VERSION "Mon"

NS_ :

BS_:

BU_: Mon ADAS Camera Gateway EPS APA Radar ESC radar
VAL_TABLE_ VitSig_LKA_main_switch 1 "LKA ON" 0 "LKA OFF" ;
VAL_TABLE_ VitSig_LC_Mode 3 "车道居中控制" 2 "车道保持辅助" 1 "车道偏离预警" 0 "预留" ;
VAL_TABLE_ VitSig_State_of_EPS_for_LKA 7 "Reserved" 6 "Reserved" 5 "Reserved" 4 "defect" 3 "active" 2 "available" 1 "authorized" 0 "unauthorized" ;
VAL_TABLE_ VitSig_Steering_wheel_sensor_dir 1 "Negative angles, decrease" 0 "Positive angles, increase" ;
VAL_TABLE_ VitSig_BCM_Status_Indicator 3 "Left and right indicator active" 2 "Left Indicator active" 1 "Right Indicator active" 0 "Indicator inactive" ;
VAL_TABLE_ VitSig_TCU_Gear_lever_position 15 "CMF disabled or unavailable" 14 "Reserved" 13 "Reserved" 12 "Reserved" 11 "Manual mode / Reserved1100" 10 "Reserved" 9 "Reserved" 8 "Reserved" 7 "Reserved" 6 "Reserved" 5 "Reserved" 4 "Reserved" 3 "D" 2 "N" 1 "R" 0 "P" ;
VAL_TABLE_ VLlaneType_valueTable 6 "road edge" 5 "bott's dotts" 4 "double lane mark" 3 "solid" 2 "dashed" 1 "undecided" 0 "invalid" ;
VAL_TABLE_ VLquality_valueTable 1 "high" 0 "low" ;

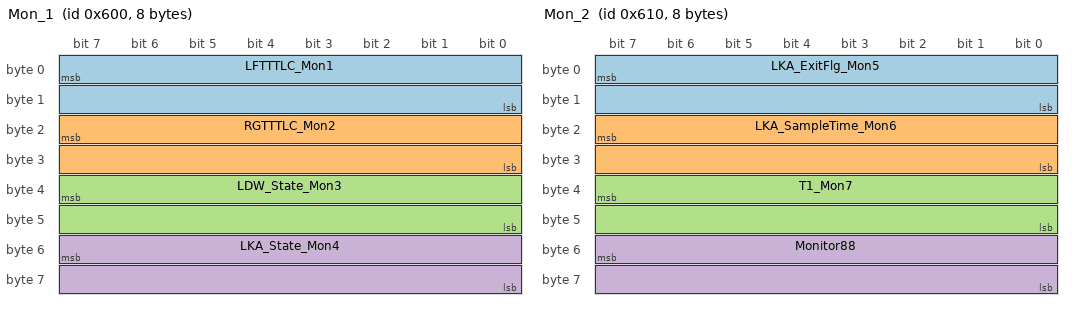
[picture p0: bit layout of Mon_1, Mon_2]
BO_ 1536 Mon_1: 8 Mon
 SG_ LFTTTLC_Mon1 : 7|16@0- (0.01,0) [-327.68|327.67] "Mon" Vector__XXX
 SG_ RGTTTLC_Mon2 : 23|16@0- (0.01,0) [-327.68|327.67] "Mon" Vector__XXX
 SG_ LDW_State_Mon3 : 39|16@0- (0.01,0) [-327.68|327.67] "Mon" Vector__XXX
 SG_ LKA_State_Mon4 : 55|16@0- (0.01,0) [-327.68|327.67] "Mon" Vector__XXX

BO_ 1552 Mon_2: 8 Mon
 SG_ LKA_ExitFlg_Mon5 : 7|16@0- (0.01,0) [-327.68|327.67] "Mon" Vector__XXX
 SG_ LKA_SampleTime_Mon6 : 23|16@0- (0.01,0) [-327.68|327.67] "Mon" Vector__XXX
 SG_ T1_Mon7 : 39|16@0- (0.01,0) [-327.68|327.67] "Mon" Vector__XXX
 SG_ Monitor88 : 55|16@0- (0.01,0) [-327.68|327.67] "Mon" Vector__XXX

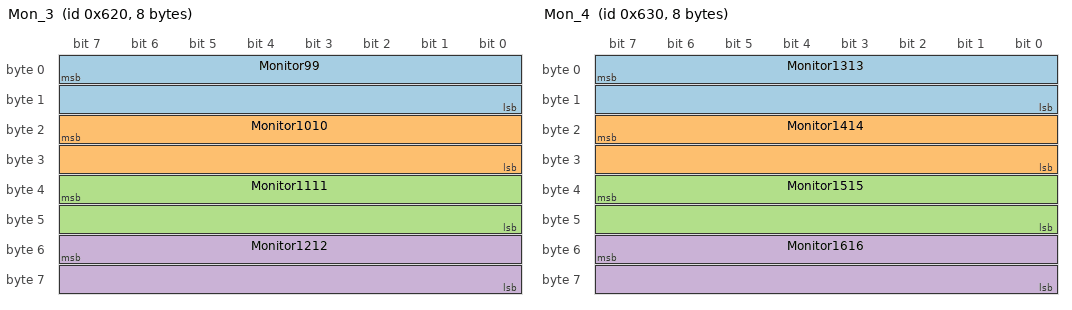
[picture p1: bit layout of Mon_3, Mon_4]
BO_ 1568 Mon_3: 8 Mon
 SG_ Monitor99 : 7|16@0- (0.01,0) [-327.68|327.67] "Mon" Vector__XXX
 SG_ Monitor1010 : 23|16@0- (0.01,0) [-327.68|327.67] "Mon" Vector__XXX
 SG_ Monitor1111 : 39|16@0- (0.01,0) [-327.68|327.67] "Mon" Vector__XXX
 SG_ Monitor1212 : 55|16@0- (0.01,0) [-327.68|327.67] "Mon" Vector__XXX

BO_ 1584 Mon_4: 8 Mon
 SG_ Monitor1313 : 7|16@0- (0.01,0) [-327.68|327.67] "Mon" Vector__XXX
 SG_ Monitor1414 : 23|16@0- (0.01,0) [-327.68|327.67] "Mon" Vector__XXX
 SG_ Monitor1515 : 39|16@0- (0.01,0) [-327.68|327.67] "Mon" Vector__XXX
 SG_ Monitor1616 : 55|16@0- (0.01,0) [-327.68|327.67] "Mon" Vector__XXX

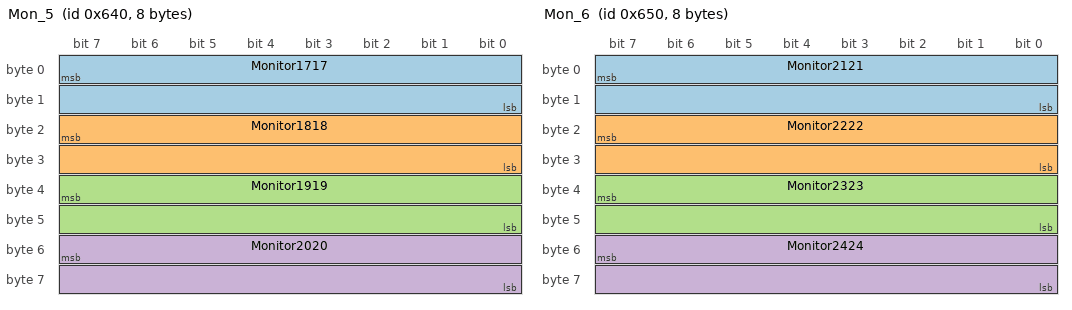
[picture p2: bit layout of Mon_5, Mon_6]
BO_ 1600 Mon_5: 8 Mon
 SG_ Monitor1717 : 7|16@0- (0.01,0) [-327.68|327.67] "Mon" Vector__XXX
 SG_ Monitor1818 : 23|16@0- (0.01,0) [-327.68|327.67] "Mon" Vector__XXX
 SG_ Monitor1919 : 39|16@0- (0.01,0) [-327.68|327.67] "Mon" Vector__XXX
 SG_ Monitor2020 : 55|16@0- (0.01,0) [-327.68|327.67] "Mon" Vector__XXX

BO_ 1616 Mon_6: 8 Mon
 SG_ Monitor2121 : 7|16@0- (0.01,0) [-327.68|327.67] "Mon" Vector__XXX
 SG_ Monitor2222 : 23|16@0- (0.01,0) [-327.68|327.67] "Mon" Vector__XXX
 SG_ Monitor2323 : 39|16@0- (0.01,0) [-327.68|327.67] "Mon" Vector__XXX
 SG_ Monitor2424 : 55|16@0- (0.01,0) [-327.68|327.67] "Mon" Vector__XXX

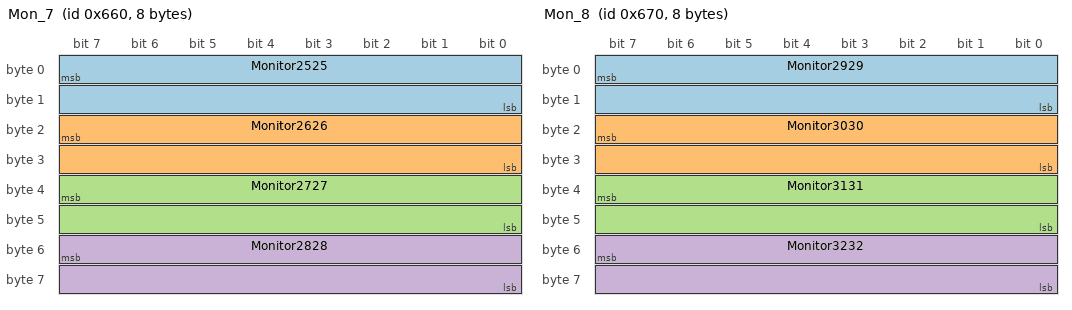
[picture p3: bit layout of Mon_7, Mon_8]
BO_ 1632 Mon_7: 8 Mon
 SG_ Monitor2525 : 7|16@0- (0.01,0) [-327.68|327.67] "Mon" Vector__XXX
 SG_ Monitor2626 : 23|16@0- (0.01,0) [-327.68|327.67] "Mon" Vector__XXX
 SG_ Monitor2727 : 39|16@0- (0.01,0) [-327.68|327.67] "Mon" Vector__XXX
 SG_ Monitor2828 : 55|16@0- (0.01,0) [-327.68|327.67] "Mon" Vector__XXX

BO_ 1648 Mon_8: 8 Mon
 SG_ Monitor2929 : 7|16@0- (0.01,0) [-327.68|327.67] "Mon" Vector__XXX
 SG_ Monitor3030 : 23|16@0- (0.01,0) [-327.68|327.67] "Mon" Vector__XXX
 SG_ Monitor3131 : 39|16@0- (0.01,0) [-327.68|327.67] "Mon" Vector__XXX
 SG_ Monitor3232 : 55|16@0- (0.01,0) [-327.68|327.67] "Mon" Vector__XXX

BO_ 1359 GW_550_PSA1: 8 Gateway
 SG_ LKA_main_switch : 5|1@0+ (1,0) [0|1] ""  ADAS,Camera
 SG_ LC_Mode : 7|2@0+ (1,0) [0|3] ""  ADAS,Camera

BO_ 1172 EPS_495_PSA1: 4 EPS
 SG_ State_of_EPS_for_LKA_function : 20|3@0+ (1,0) [0|7] ""  ADAS,Camera
 SG_ Steering_wheel_torque : 7|8@0- (0.25,0) [-32|31.5] "N.m"  ADAS,Camera

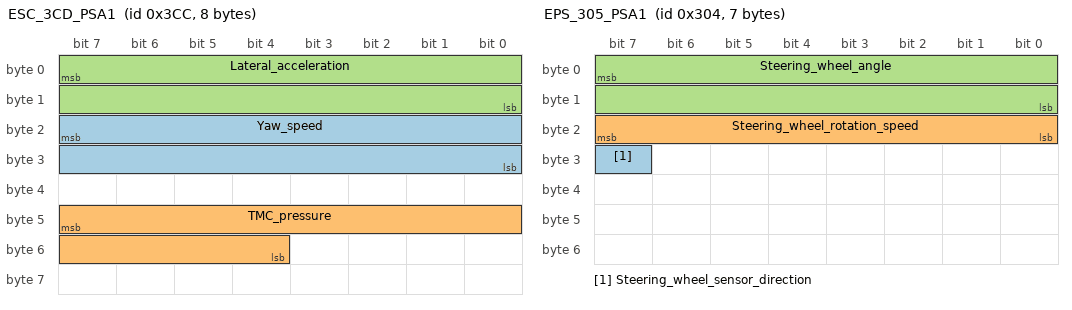
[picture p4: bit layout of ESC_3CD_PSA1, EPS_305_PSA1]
BO_ 972 ESC_3CD_PSA1: 8 ESC
 SG_ Yaw_speed : 23|16@0- (0.1,0) [-100|100] "Degree/s"  EPS,Gateway,APA,Camera,ADAS
 SG_ TMC_pressure : 47|12@0+ (0.1,-55) [-55|354.4] "Bar"  Gateway,APA,Radar,Camera,ADAS
 SG_ Lateral_acceleration : 7|16@0- (0.05,0) [-15|15] "m/s2"  EPS,Gateway,APA,Radar,Camera,ADAS

BO_ 908 ESC_38D_PSA1: 8 ESC
 SG_ Vehicle_speed_of_wheelsensor : 7|16@0+ (0.01,0) [0|655.34] "km/h"  EPS,Gateway,APA,Radar,Camera,ADAS

BO_ 812 GW_32D_PSA1: 8 Gateway
 SG_ ACCEL_LONGI_CALIB : 7|12@0+ (0.02,-40.96) [-40.96|40.92] "m/s2"  Radar,Camera,ADAS

BO_ 772 EPS_305_PSA1: 7 EPS
 SG_ Steering_wheel_sensor_direction : 31|1@0+ (1,0) [0|0] ""  ADAS,Camera,ESC,Gateway,Radar
 SG_ Steering_wheel_rotation_speed : 23|8@0+ (4,0) [0|1016] "Degree/s"  ADAS,APA,Camera,ESC,Gateway,Radar
 SG_ Steering_wheel_angle : 7|16@0- (0.1,0) [-780|780] "Degree"  ADAS,APA,Camera,ESC,Gateway,Radar

BO_ 1105 GW_452_PSA1: 6 Gateway
 SG_ BCM_Status_Indicator : 5|2@0+ (1,0) [0|0] ""  APA,Radar,Camera,ADAS

BO_ 840 GW_349_PSA1: 8 Gateway
 SG_ TCU_Gear_lever_position : 27|4@0+ (1,0) [0|0] ""  ESC,APA,Radar,Camera,ADAS

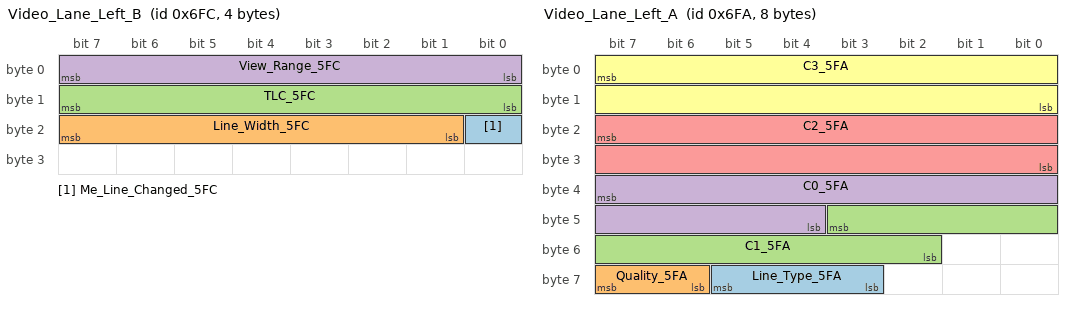
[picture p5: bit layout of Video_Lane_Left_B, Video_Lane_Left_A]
BO_ 1788 Video_Lane_Left_B: 4 Camera
 SG_ Me_Line_Changed_5FC : 16|1@0+ (1,0) [0|1] ""  radar,ADAS
 SG_ Line_Width_5FC : 23|7@0+ (0.01,0) [0|1.27] "m"  radar,ADAS
 SG_ TLC_5FC : 15|8@0+ (0.01,0) [0|2.55] "s"  radar,ADAS
 SG_ View_Range_5FC : 7|8@0+ (0.5,0) [0|127.5] "m"  radar,ADAS

BO_ 1786 Video_Lane_Left_A: 8 Camera
 SG_ Line_Type_5FA : 61|3@0+ (1,0) [0|7] ""  radar,ADAS
 SG_ Quality_5FA : 63|2@0+ (1,0) [0|3] ""  radar,ADAS
 SG_ C1_5FA : 43|10@0- (0.0009765625,0) [-0.357|0.357] ""  radar,ADAS
 SG_ C0_5FA : 39|12@0- (0.01,0) [-20.48|20.47] "m"  radar,ADAS
 SG_ C2_5FA : 23|16@0- (1E-006,0) [-0.032768|0.032766] "m-1"  radar,ADAS
 SG_ C3_5FA : 7|16@0- (4E-009,0) [-0.000131072|0.000131068] "m-2"  radar,ADAS

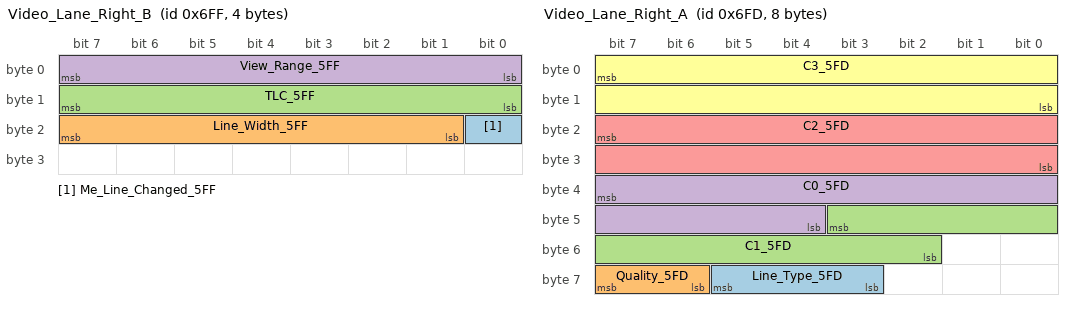
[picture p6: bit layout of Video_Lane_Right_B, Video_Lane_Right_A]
BO_ 1791 Video_Lane_Right_B: 4 Camera
 SG_ Me_Line_Changed_5FF : 16|1@0+ (1,0) [0|1] ""  radar,ADAS
 SG_ Line_Width_5FF : 23|7@0+ (0.01,0) [0|1.27] "m"  radar,ADAS
 SG_ TLC_5FF : 15|8@0+ (0.01,0) [0|2.55] "s"  radar,ADAS
 SG_ View_Range_5FF : 7|8@0+ (0.5,0) [0|127.5] "m"  radar,ADAS

BO_ 1789 Video_Lane_Right_A: 8 Camera
 SG_ Line_Type_5FD : 61|3@0+ (1,0) [0|7] ""  radar,ADAS
 SG_ Quality_5FD : 63|2@0+ (1,0) [0|3] ""  radar,ADAS
 SG_ C1_5FD : 43|10@0- (0.0009765625,0) [-0.357|0.357] ""  radar,ADAS
 SG_ C0_5FD : 39|12@0- (0.01,0) [-20.48|20.47] "m"  radar,ADAS
 SG_ C2_5FD : 23|16@0- (1E-006,0) [-0.032768|0.032766] "m-1"  radar,ADAS
 SG_ C3_5FD : 7|16@0- (4E-009,0) [-0.000131072|0.000131068] "m-2"  radar,ADAS

CM_ SG_ 1359 LKA_main_switch "LKA开启开关";
CM_ SG_ 1359 LC_Mode "LKA功能选择";
CM_ SG_ 1172 State_of_EPS_for_LKA_function "LKA功能的EPS状态";
CM_ SG_ 1172 Steering_wheel_torque "方向盘转矩";
CM_ SG_ 972 Yaw_speed "横摆角速度";
CM_ SG_ 972 TMC_pressure "主缸压力";
CM_ SG_ 972 Lateral_acceleration "侧向加速度";
CM_ SG_ 908 Vehicle_speed_of_wheelsensor "车速（轮速传感器)";
CM_ SG_ 812 ACCEL_LONGI_CALIB "标定后的当前纵向加速度";
CM_ SG_ 772 Steering_wheel_sensor_direction "转向传感器方向";
CM_ SG_ 772 Steering_wheel_rotation_speed "转向旋转速度";
CM_ SG_ 772 Steering_wheel_angle "转向角信号";
CM_ SG_ 1105 BCM_Status_Indicator "转向灯状态（包括双闪）";
CM_ SG_ 840 TCU_Gear_lever_position "换挡手柄位置";
CM_ SG_ 1788 Me_Line_Changed_5FC "is one for one cycle when lane model switched.";
CM_ SG_ 1786 C1_5FA "57 degrees, 0.06 degrees resolution";
CM_ SG_ 1786 C2_5FA "250m minimal radius";
CM_ SG_ 1791 Me_Line_Changed_5FF "is one for one cycle when lane model switched.";
CM_ SG_ 1789 C1_5FD "57 degrees, 0.06 degrees resolution";
CM_ SG_ 1789 C2_5FD "250m minimal radius";
BA_DEF_  "BusType" STRING ;
BA_DEF_DEF_  "BusType" "CAN";
VAL_ 1359 LKA_main_switch 1 "LKA ON" 0 "LKA OFF" ;
VAL_ 1359 LC_Mode 3 "车道居中控制" 2 "车道保持辅助" 1 "车道偏离预警" 0 "预留" ;
VAL_ 1172 State_of_EPS_for_LKA_function 7 "Reserved" 6 "Reserved" 5 "Reserved" 4 "defect" 3 "active" 2 "available" 1 "authorized" 0 "unauthorized" ;
VAL_ 772 Steering_wheel_sensor_direction 1 "Negative angles, decrease" 0 "Positive angles, increase" ;
VAL_ 1105 BCM_Status_Indicator 3 "Left and right indicator active" 2 "Left Indicator active" 1 "Right Indicator active" 0 "Indicator inactive" ;
VAL_ 1786 Line_Type_5FA 5 "bott's dotts" 4 "double lane mark" 3 "dashed" 2 "road edge" 1 "solid" 0 "undecided" ;
VAL_ 1786 Quality_5FA 3 "High" 2 "Medium_PredictedOrLowScore" 1 "Low2_InsufficientScore" 0 "Low1_NoLineDetected" ;
